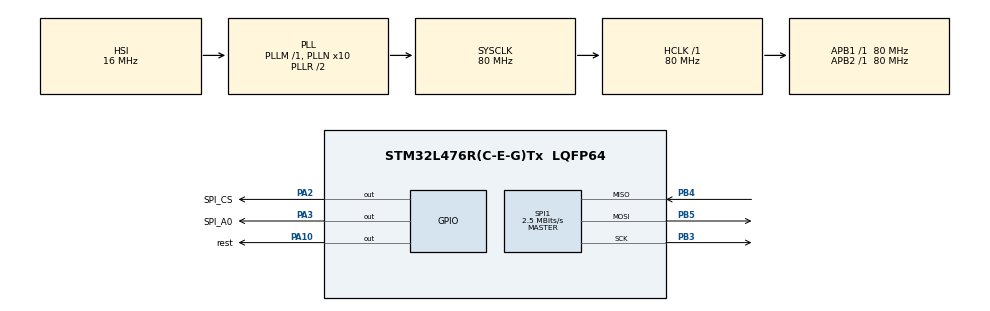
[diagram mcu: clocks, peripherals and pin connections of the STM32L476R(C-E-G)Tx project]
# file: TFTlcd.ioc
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Mcu.Family=STM32L4
Mcu.Name=STM32L476R(C-E-G)Tx
Mcu.Package=LQFP64
NVIC.PriorityGroup=NVIC_PRIORITYGROUP_4
PA10.GPIO_Label=rest
PA10.PinState=GPIO_PIN_SET
PA10.Signal=GPIO_Output
PA2.GPIO_Label=SPI_CS
PA2.PinState=GPIO_PIN_SET
PA2.Signal=GPIO_Output
PA3.GPIO_Label=SPI_A0
PA3.Signal=GPIO_Output
PB3\ (JTDO-TRACESWO).Mode=Full_Duplex_Master
PB3\ (JTDO-TRACESWO).Signal=SPI1_SCK
PB4\ (NJTRST).Mode=Full_Duplex_Master
PB4\ (NJTRST).Signal=SPI1_MISO
PB5.Mode=Full_Duplex_Master
PB5.Signal=SPI1_MOSI
ProjectManager.HeapSize=0x200
ProjectManager.StackSize=0x400
ProjectManager.TargetToolchain=STM32CubeIDE
RCC.ADCFreq_Value=64000000
RCC.AHBFreq_Value=80000000
RCC.APB1Freq_Value=80000000
RCC.APB1TimFreq_Value=80000000
RCC.APB2Freq_Value=80000000
RCC.APB2TimFreq_Value=80000000
RCC.CortexFreq_Value=80000000
RCC.HCLKFreq_Value=80000000
RCC.HSE_VALUE=8000000
RCC.HSI_VALUE=16000000
RCC.LSE_VALUE=32768
RCC.MSI_VALUE=4000000
RCC.PLLN=10
RCC.PLLSourceVirtual=RCC_PLLSOURCE_HSI
RCC.SYSCLKFreq_VALUE=80000000
RCC.SYSCLKSource=RCC_SYSCLKSOURCE_PLLCLK
RCC.USBFreq_Value=64000000
RCC.VCOOutputFreq_Value=160000000
SPI1.BaudRatePrescaler=SPI_BAUDRATEPRESCALER_32
SPI1.CalculateBaudRate=2.5 MBits/s
SPI1.DataSize=SPI_DATASIZE_8BIT
SPI1.Direction=SPI_DIRECTION_2LINES
SPI1.Mode=SPI_MODE_MASTER
SPI1.VirtualType=VM_MASTER
board=custom

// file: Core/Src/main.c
/* USER CODE BEGIN Header */
/**
  ******************************************************************************
  * @file           : main.c
  * @brief          : Main program body
  ******************************************************************************
  * @attention
  *
  * <h2><center>&copy; Copyright (c) 2019 STMicroelectronics.
  * All rights reserved.</center></h2>
  *
  * This software component is licensed by ST under BSD 3-Clause license,
  * the "License"; You may not use this file except in compliance with the
  * License. You may obtain a copy of the License at:
  *                        opensource.org/licenses/BSD-3-Clause
  *
  ******************************************************************************
  */
/* USER CODE END Header */

#include "main.h"
#include "spi.h"
#include "gpio.h"

/* USER CODE BEGIN Includes */
#include "lcd.h"
#include "gui.h"
/* USER CODE END Includes */

void SystemClock_Config(void);

int main(void)
{

  /* MCU Configuration--------------------------------------------------------*/

  /* Reset of all peripherals, Initializes the Flash interface and the Systick. */
  HAL_Init();

  /* Configure the system clock */
  SystemClock_Config();

  /* Initialize all configured peripherals */
  MX_GPIO_Init();
  MX_SPI1_Init();
  /* USER CODE BEGIN 2 */
  LCD_RESET();
  red_reg();
  LCD_Init();
  LCD_direction(USE_HORIZONTAL);
  red_reg();
  HAL_Delay(1000);
 // red_reg();
 // LCD_Clear(BRED);
  /* USER CODE END 2 */

  /* Infinite loop */
  /* USER CODE BEGIN WHILE */
  while (1)
  {
	  LCD_ShowString(20,30,12,(uint8_t *)"hello",0);
	  HAL_Delay(5000);
	  Show_Str(10,120,BLUE,YELLOW,"8X16:~!@#$%^&*()_+{}:<>?/|-+.",16,0);
    /* USER CODE END WHILE */

  }
}

void SystemClock_Config(void)
{
  RCC_OscInitTypeDef RCC_OscInitStruct = {0};
  RCC_ClkInitTypeDef RCC_ClkInitStruct = {0};

  /** Initializes the CPU, AHB and APB busses clocks
  */
  RCC_OscInitStruct.OscillatorType = RCC_OSCILLATORTYPE_HSI;
  RCC_OscInitStruct.HSIState = RCC_HSI_ON;
  RCC_OscInitStruct.HSICalibrationValue = RCC_HSICALIBRATION_DEFAULT;
  RCC_OscInitStruct.PLL.PLLState = RCC_PLL_ON;
  RCC_OscInitStruct.PLL.PLLSource = RCC_PLLSOURCE_HSI;
  RCC_OscInitStruct.PLL.PLLM = 1;
  RCC_OscInitStruct.PLL.PLLN = 10;
  RCC_OscInitStruct.PLL.PLLP = RCC_PLLP_DIV7;
  RCC_OscInitStruct.PLL.PLLQ = RCC_PLLQ_DIV2;
  RCC_OscInitStruct.PLL.PLLR = RCC_PLLR_DIV2;
  if (HAL_RCC_OscConfig(&RCC_OscInitStruct) != HAL_OK)
  {
    Error_Handler();
  }
  /** Initializes the CPU, AHB and APB busses clocks
  */
  RCC_ClkInitStruct.ClockType = RCC_CLOCKTYPE_HCLK|RCC_CLOCKTYPE_SYSCLK
                              |RCC_CLOCKTYPE_PCLK1|RCC_CLOCKTYPE_PCLK2;
  RCC_ClkInitStruct.SYSCLKSource = RCC_SYSCLKSOURCE_PLLCLK;
  RCC_ClkInitStruct.AHBCLKDivider = RCC_SYSCLK_DIV1;
  RCC_ClkInitStruct.APB1CLKDivider = RCC_HCLK_DIV1;
  RCC_ClkInitStruct.APB2CLKDivider = RCC_HCLK_DIV1;

  if (HAL_RCC_ClockConfig(&RCC_ClkInitStruct, FLASH_LATENCY_4) != HAL_OK)
  {
    Error_Handler();
  }
  /** Configure the main internal regulator output voltage
  */
  if (HAL_PWREx_ControlVoltageScaling(PWR_REGULATOR_VOLTAGE_SCALE1) != HAL_OK)
  {
    Error_Handler();
  }
}

void Error_Handler(void)
{
}

/************************ (C) COPYRIGHT STMicroelectronics *****END OF FILE****/
